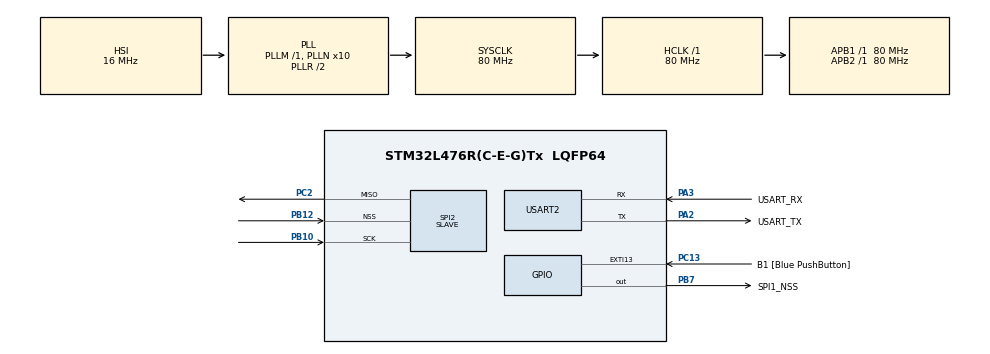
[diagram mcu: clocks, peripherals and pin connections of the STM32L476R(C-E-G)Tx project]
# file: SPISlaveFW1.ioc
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Mcu.Family=STM32L4
PA2.GPIO_PuPd=GPIO_NOPULL
Dma.SPI2_TX.0.MemInc=DMA_MINC_ENABLE
SPI2.VirtualNSS=VM_NSSHARD
RCC.CortexFreq_Value=80000000
NVIC.DMA1_Channel5_IRQn=true\:0\:0\:false\:false\:true\:false\:true
SPI2.VirtualType=VM_SLAVE
PB10.Mode=TX_Only_Simplex_Unidirect_Slave
PH0-OSC_IN\ (PH0).Signal=RCC_OSC_IN
PA3.GPIO_PuPd=GPIO_NOPULL
PA2.GPIO_Speed=GPIO_SPEED_FREQ_VERY_HIGH
PC15-OSC32_OUT\ (PC15).Mode=LSE-External-Oscillator
PC13.GPIO_Label=B1 [Blue PushButton]
PA3.GPIO_Speed=GPIO_SPEED_FREQ_VERY_HIGH
Dma.SPI2_TX.0.Instance=DMA1_Channel5
RCC.SYSCLKSource=RCC_SYSCLKSOURCE_PLLCLK
ProjectManager.StackSize=0x400
PB3\ (JTDO-TRACESWO).Signal=SYS_JTDO-SWO
PC14-OSC32_IN\ (PC14).Mode=LSE-External-Oscillator
Dma.SPI2_TX.0.MemDataAlignment=DMA_MDATAALIGN_BYTE
PA14\ (JTCK-SWCLK).Signal=SYS_JTCK-SWCLK
RCC.HCLKFreq_Value=80000000
RCC.APB2TimFreq_Value=80000000
Dma.SPI2_TX.0.Mode=DMA_NORMAL
RCC.AHBFreq_Value=80000000
RCC.PREFETCH_ENABLE=1
RCC.HSE_VALUE=8000000
USART2.VirtualMode-Asynchronous=VM_ASYNC
PC13.GPIO_PuPd=GPIO_NOPULL
PB7.Signal=GPIO_Output
NVIC.SPI2_IRQn=true\:0\:0\:false\:false\:true\:true\:true
PB7.PinState=GPIO_PIN_SET
PB7.GPIO_Label=SPI1_NSS
Mcu.Package=LQFP64
PB12.Mode=NSS_Signal_Hard_Input
SPI2.Mode=SPI_MODE_SLAVE
PA2.GPIO_Label=USART_TX
Dma.SPI2_TX.0.PeriphInc=DMA_PINC_DISABLE
RCC.APB1TimFreq_Value=80000000
SPI2.Direction=SPI_DIRECTION_2LINES
PA13\ (JTMS-SWDIO).Signal=SYS_JTMS-SWDIO
Dma.Request0=SPI2_TX
PA3.Signal=USART2_RX
PA2.GPIO_Mode=GPIO_MODE_AF_PP
RCC.MSI_VALUE=4000000
RCC.PLLSourceVirtual=RCC_PLLSOURCE_HSI
PA14\ (JTCK-SWCLK).Mode=Serial_Wire
PC13.Signal=GPXTI13
PC2.Signal=SPI2_MISO
PC2.Mode=TX_Only_Simplex_Unidirect_Slave
PC15-OSC32_OUT\ (PC15).Signal=RCC_OSC32_OUT
PA14\ (JTCK-SWCLK).GPIO_Label=TCK
PB3\ (JTDO-TRACESWO).GPIO_Label=SWO
PH1-OSC_OUT\ (PH1).Signal=RCC_OSC_OUT
PA3.Mode=Asynchronous
ProjectManager.TargetToolchain=Makefile
PA3.GPIO_Mode=GPIO_MODE_AF_PP
RCC.USBFreq_Value=64000000
PB10.Signal=SPI2_SCK
board=NUCLEO-L476RG
RCC.VCOOutputFreq_Value=160000000
RCC.APB2Freq_Value=80000000
PA13\ (JTMS-SWDIO).GPIO_Label=TMS
Dma.SPI2_TX.0.PeriphDataAlignment=DMA_PDATAALIGN_BYTE
RCC.ADCFreq_Value=64000000
Mcu.Name=STM32L476R(C-E-G)Tx
PA2.Signal=USART2_TX
PA13\ (JTMS-SWDIO).Mode=Serial_Wire
Dma.SPI2_TX.0.Priority=DMA_PRIORITY_LOW
RCC.SYSCLKFreq_VALUE=80000000
PC13.GPIO_ModeDefaultEXTI=GPIO_MODE_IT_FALLING
PC14-OSC32_IN\ (PC14).Signal=RCC_OSC32_IN
ProjectManager.HeapSize=0x200
RCC.HSI_VALUE=16000000
NVIC.PriorityGroup=NVIC_PRIORITYGROUP_4
RCC.PLLN=10
PA2.Mode=Asynchronous
SPI2.DataSize=SPI_DATASIZE_8BIT
Dma.SPI2_TX.0.Direction=DMA_MEMORY_TO_PERIPH
RCC.APB1Freq_Value=80000000
PB12.Signal=SPI2_NSS
PA3.GPIO_Label=USART_RX

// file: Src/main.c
/* USER CODE BEGIN Header */
/**
  ******************************************************************************
  * @file           : main.c
  * @brief          : Main program body
  ******************************************************************************
  * @attention
  *
  * <h2><center>&copy; Copyright (c) 2021 STMicroelectronics.
  * All rights reserved.</center></h2>
  *
  * This software component is licensed by ST under BSD 3-Clause license,
  * the "License"; You may not use this file except in compliance with the
  * License. You may obtain a copy of the License at:
  *                        opensource.org/licenses/BSD-3-Clause
  *
  ******************************************************************************
  */
/* USER CODE END Header */
#include "main.h"
#include "dma.h"
#include "spi.h"
#include "usart.h"
#include "gpio.h"

/* USER CODE BEGIN PD */
#define BUF_SIZE 40
/* USER CODE END PD */

/* USER CODE BEGIN PV */
uint8_t txBuffer[BUF_SIZE] = {
  1, 2, 3, 4, 5, 6, 7, 8, 9, 10,
  11, 12, 13, 14, 15, 16, 17, 18, 19, 20,
  21, 22, 23, 24, 25, 26, 27, 28, 29, 30,
  31, 32, 33, 34, 35, 36, 37, 38, 39, 40,
};
/* USER CODE END PV */

void SystemClock_Config(void);

int main(void)
{

  /* MCU Configuration--------------------------------------------------------*/

  /* Reset of all peripherals, Initializes the Flash interface and the Systick. */
  HAL_Init();

  /* Configure the system clock */
  SystemClock_Config();

  /* Initialize all configured peripherals */
  MX_GPIO_Init();
  MX_DMA_Init();
  MX_USART2_UART_Init();
  MX_SPI2_Init();
  /* USER CODE BEGIN 2 */
  HAL_SPI_Transmit_DMA(&hspi2, txBuffer, sizeof(txBuffer));
  /* USER CODE END 2 */

  /* Infinite loop */
  while (1)
  {

  }
}

void SystemClock_Config(void)
{
  RCC_OscInitTypeDef RCC_OscInitStruct = {0};
  RCC_ClkInitTypeDef RCC_ClkInitStruct = {0};
  RCC_PeriphCLKInitTypeDef PeriphClkInit = {0};

  /** Initializes the RCC Oscillators according to the specified parameters
  * in the RCC_OscInitTypeDef structure.
  */
  RCC_OscInitStruct.OscillatorType = RCC_OSCILLATORTYPE_HSI;
  RCC_OscInitStruct.HSIState = RCC_HSI_ON;
  RCC_OscInitStruct.HSICalibrationValue = RCC_HSICALIBRATION_DEFAULT;
  RCC_OscInitStruct.PLL.PLLState = RCC_PLL_ON;
  RCC_OscInitStruct.PLL.PLLSource = RCC_PLLSOURCE_HSI;
  RCC_OscInitStruct.PLL.PLLM = 1;
  RCC_OscInitStruct.PLL.PLLN = 10;
  RCC_OscInitStruct.PLL.PLLP = RCC_PLLP_DIV7;
  RCC_OscInitStruct.PLL.PLLQ = RCC_PLLQ_DIV2;
  RCC_OscInitStruct.PLL.PLLR = RCC_PLLR_DIV2;
  if (HAL_RCC_OscConfig(&RCC_OscInitStruct) != HAL_OK)
  {
    Error_Handler();
  }
  /** Initializes the CPU, AHB and APB buses clocks
  */
  RCC_ClkInitStruct.ClockType = RCC_CLOCKTYPE_HCLK|RCC_CLOCKTYPE_SYSCLK
                              |RCC_CLOCKTYPE_PCLK1|RCC_CLOCKTYPE_PCLK2;
  RCC_ClkInitStruct.SYSCLKSource = RCC_SYSCLKSOURCE_PLLCLK;
  RCC_ClkInitStruct.AHBCLKDivider = RCC_SYSCLK_DIV1;
  RCC_ClkInitStruct.APB1CLKDivider = RCC_HCLK_DIV1;
  RCC_ClkInitStruct.APB2CLKDivider = RCC_HCLK_DIV1;

  if (HAL_RCC_ClockConfig(&RCC_ClkInitStruct, FLASH_LATENCY_4) != HAL_OK)
  {
    Error_Handler();
  }
  PeriphClkInit.PeriphClockSelection = RCC_PERIPHCLK_USART2;
  PeriphClkInit.Usart2ClockSelection = RCC_USART2CLKSOURCE_PCLK1;
  if (HAL_RCCEx_PeriphCLKConfig(&PeriphClkInit) != HAL_OK)
  {
    Error_Handler();
  }
  /** Configure the main internal regulator output voltage
  */
  if (HAL_PWREx_ControlVoltageScaling(PWR_REGULATOR_VOLTAGE_SCALE1) != HAL_OK)
  {
    Error_Handler();
  }
}

/* USER CODE BEGIN 4 */
void HAL_SPI_TxCpltCallback(SPI_HandleTypeDef* hspi)
{
  if(hspi == &hspi2){
    HAL_SPI_Transmit_DMA(&hspi2, txBuffer, sizeof(txBuffer));
  }
}
/* USER CODE END 4 */

void Error_Handler(void)
{
  __disable_irq();
  while (1)
  {
  }
}

/************************ (C) COPYRIGHT STMicroelectronics *****END OF FILE****/
